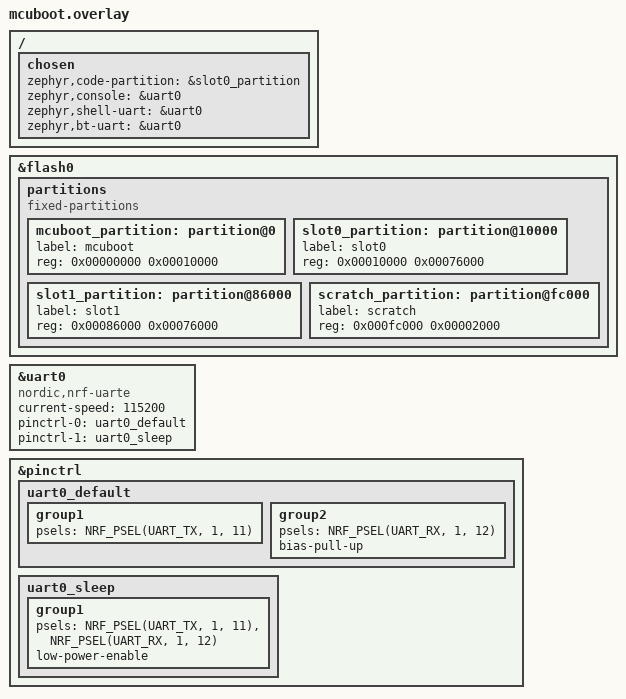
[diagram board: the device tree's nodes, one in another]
/*
 * Copyright (c) 2024
 * SPDX-License-Identifier: Apache-2.0
 */

/ {
	chosen {
		zephyr,code-partition = &slot0_partition;
		zephyr,console = &uart0;
		zephyr,shell-uart = &uart0;
		zephyr,bt-uart = &uart0;
	};
};

/* Delete the existing partition layout */
/delete-node/ &{/soc/flash-controller@4001e000/flash@0/partitions};

/* MCUboot partition layout for nRF52840 */
&flash0 {
	partitions {
		compatible = "fixed-partitions";
		#address-cells = <1>;
		#size-cells = <1>;

		mcuboot_partition: partition@0 {
			label = "mcuboot";
			reg = <0x00000000 0x00010000>;
		};

		slot0_partition: partition@10000 {
			label = "slot0";
			reg = <0x00010000 0x00076000>;
		};

		slot1_partition: partition@86000 {
			label = "slot1";
			reg = <0x00086000 0x00076000>;
		};

		scratch_partition: partition@fc000 {
			label = "scratch";
			reg = <0x000fc000 0x00002000>;
		};
	};
};

/* UART configuration */
&uart0 {
	compatible = "nordic,nrf-uarte";
	status = "okay";
	current-speed = <115200>;
	pinctrl-0 = <&uart0_default>;
	pinctrl-1 = <&uart0_sleep>;
	pinctrl-names = "default", "sleep";
};

&pinctrl {
	uart0_default: uart0_default {
		group1 {
			/* TX pin - P1.11 (Pin D6) */
			psels = <NRF_PSEL(UART_TX, 1, 11)>;
		};
		group2 {
			/* RX pin - P1.12 (Pin D7) */
			psels = <NRF_PSEL(UART_RX, 1, 12)>;
			bias-pull-up;
		};
	};

	uart0_sleep: uart0_sleep {
		group1 {
			psels = <NRF_PSEL(UART_TX, 1, 11)>,
				<NRF_PSEL(UART_RX, 1, 12)>;
			low-power-enable;
		};
	};
};
